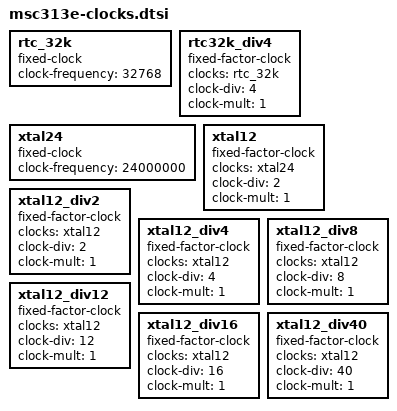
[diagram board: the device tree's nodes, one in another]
// SPDX-License-Identifier: GPL-2.0
/*
 * Copyright (c) 2019 thingy.jp.
 * Author: Daniel Palmer <daniel@0x0f.com>
 *
 */

/*
 * For the msc313e there is no rtc/32khz input so presumably this clock
 * doesn't actually work.
 */

rtc_32k: rtc_32k {
	#clock-cells = <0>;
	compatible = "fixed-clock";
	clock-frequency = <32768>;
};

rtc32k_div4: rtc32k_div4 {
	compatible = "fixed-factor-clock";
	#clock-cells = <0>;
	clocks = <&rtc_32k>;
	clock-div = <4>;
	clock-mult = <1>;
};

/* 
 * For the msc313e there is only a 24mhz clock input so everything else must come
 * from this base clock unless there are some on-die oscillators that aren't mentioned
 * anywhere.
 */

xtal24: xtal24 {
	#clock-cells = <0>;
	compatible = "fixed-clock";
	clock-frequency = <24000000>;
};

xtal12: xtal12 {
	#clock-cells = <0>;
	compatible = "fixed-factor-clock";
    clocks = <&xtal24>;
    clock-div = <2>;
    clock-mult = <1>;
};

xtal12_div2: xtal12_div2 {
	compatible = "fixed-factor-clock";
	#clock-cells = <0>;
	clocks = <&xtal12>;
	clock-div = <2>;
	clock-mult = <1>;
};

xtal12_div4: xtal12_div4 {
	compatible = "fixed-factor-clock";
	#clock-cells = <0>;
	clocks = <&xtal12>;
	clock-div = <4>;
	clock-mult = <1>;
};

xtal12_div8: xtal12_div8 {
	compatible = "fixed-factor-clock";
	#clock-cells = <0>;
	clocks = <&xtal12>;
	clock-div = <8>;
	clock-mult = <1>;
};

xtal12_div12: xtal12_div12 {
	compatible = "fixed-factor-clock";
	#clock-cells = <0>;
	clocks = <&xtal12>;
	clock-div = <12>;
	clock-mult = <1>;
};

xtal12_div16: xtal12_div16 {
	compatible = "fixed-factor-clock";
	#clock-cells = <0>;
	clocks = <&xtal12>;
	clock-div = <16>;
	clock-mult = <1>;
};

xtal12_div40: xtal12_div40 {
	compatible = "fixed-factor-clock";
	#clock-cells = <0>;
	clocks = <&xtal12>;
	clock-div = <40>;
	clock-mult = <1>;
};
